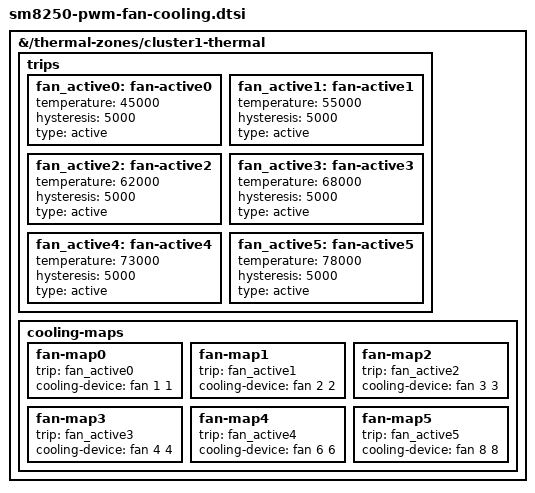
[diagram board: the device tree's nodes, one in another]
// SPDX-License-Identifier: BSD-3-Clause
/*
 * Bind the PWM fan to a thermal zone so the kernel drives it.
 *
 */

&{/thermal-zones/cluster1-thermal} {
	trips {
		fan_active0: fan-active0 {
			temperature = <45000>;
			hysteresis = <5000>;
			type = "active";
		};

		fan_active1: fan-active1 {
			temperature = <55000>;
			hysteresis = <5000>;
			type = "active";
		};

		fan_active2: fan-active2 {
			temperature = <62000>;
			hysteresis = <5000>;
			type = "active";
		};

		fan_active3: fan-active3 {
			temperature = <68000>;
			hysteresis = <5000>;
			type = "active";
		};

		fan_active4: fan-active4 {
			temperature = <73000>;
			hysteresis = <5000>;
			type = "active";
		};

		fan_active5: fan-active5 {
			temperature = <78000>;
			hysteresis = <5000>;
			type = "active";
		};
	};

	cooling-maps {
		fan-map0 {
			trip = <&fan_active0>;
			cooling-device = <&fan 1 1>;
		};

		fan-map1 {
			trip = <&fan_active1>;
			cooling-device = <&fan 2 2>;
		};

		fan-map2 {
			trip = <&fan_active2>;
			cooling-device = <&fan 3 3>;
		};

		fan-map3 {
			trip = <&fan_active3>;
			cooling-device = <&fan 4 4>;
		};

		fan-map4 {
			trip = <&fan_active4>;
			cooling-device = <&fan 6 6>;
		};

		fan-map5 {
			trip = <&fan_active5>;
			cooling-device = <&fan 8 8>;
		};
	};
};
